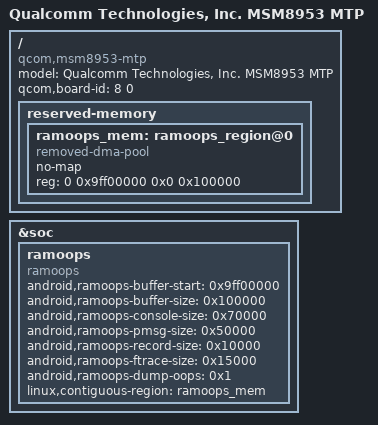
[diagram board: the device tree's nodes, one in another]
/*
 * Copyright (c) 2015-2016, The Linux Foundation. All rights reserved.
 *
 * This program is free software; you can redistribute it and/or modify
 * it under the terms of the GNU General Public License version 2 and
 * only version 2 as published by the Free Software Foundation.
 *
 * This program is distributed in the hope that it will be useful,
 * but WITHOUT ANY WARRANTY; without even the implied warranty of
 * MERCHANTABILITY or FITNESS FOR A PARTICULAR PURPOSE.  See the
 * GNU General Public License for more details.
 */

/dts-v1/;

#include "NX551/msm8953.dtsi"
#include "NX551/msm8953-mtp.dtsi"
#include "NX551/msm8953-mtp-breathlight.dtsi"

/ {
	model = "Qualcomm Technologies, Inc. MSM8953 MTP";
	compatible = "qcom,msm8953-mtp", "qcom,msm8953", "qcom,mtp";
	qcom,board-id= <8 0>;
	reserved-memory {
                ramoops_mem: ramoops_region@0 {
                        compatible = "removed-dma-pool";
                        no-map;
                        reg = <0 0x9ff00000 0x0 0x100000>;
                };
        };

};




&soc {
        ramoops {
                compatible = "ramoops";
                status = "ok";

                /* This is tacked at the end of wcnss_fw_region@0 */
                android,ramoops-buffer-start = <0x9ff00000>;
                android,ramoops-buffer-size = <0x100000>;
                android,ramoops-console-size = <0x70000>;
                android,ramoops-pmsg-size = <0x50000>;
                android,ramoops-record-size = <0x10000>;
                android,ramoops-ftrace-size = <0x15000>;
                android,ramoops-dump-oops = <0x1>;
                linux,contiguous-region = <&ramoops_mem>;
        };
};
